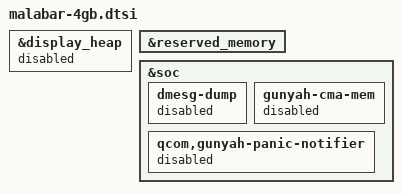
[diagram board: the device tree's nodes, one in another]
// SPDX-License-Identifier: BSD-3-Clause
/*
 * Copyright (c) Qualcomm Technologies, Inc. and/or its subsidiaries.
 */

#include "malabar.dtsi"

&display_heap {
	status = "disabled";
};

&reserved_memory {
	/delete-node/ oem_vm_mem@f7c00000;
	/delete-node/ trust_ui_vm_mem@f3800000;
	/delete-node/ vm_comm_mem;
	/delete-node/ non_secure_display_memory;
};

&soc {
	/* Delete old reserved_mmeory & add new node here */
	dmesg-dump {
		status = "disabled";
	};

	gunyah-cma-mem {
		status = "disabled";
	};

	qcom,gunyah-panic-notifier {
		status = "disabled";
	};
};
